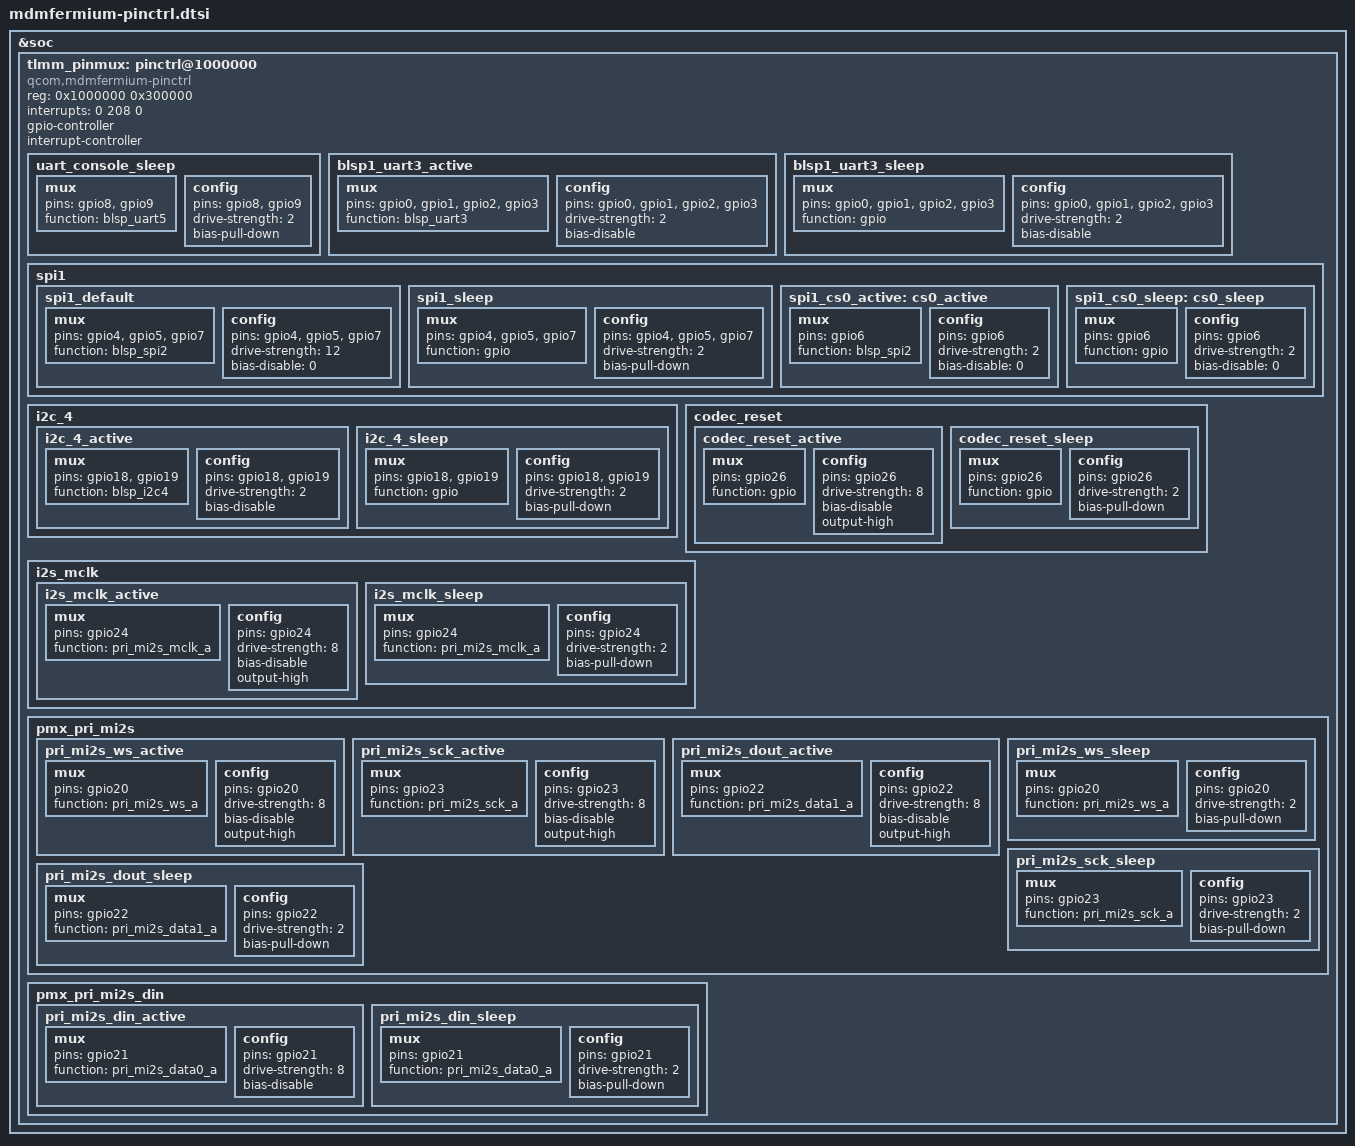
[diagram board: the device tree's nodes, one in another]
/*
 * Copyright (c) 2015, The Linux Foundation. All rights reserved.
 *
 * This program is free software; you can redistribute it and/or modify
 * it under the terms of the GNU General Public License version 2 and
 * only version 2 as published by the Free Software Foundation.
 *
 * This program is distributed in the hope that it will be useful,
 * but WITHOUT ANY WARRANTY; without even the implied warranty of
 * MERCHANTABILITY or FITNESS FOR A PARTICULAR PURPOSE.  See the
 * GNU General Public License for more details.
 */

&soc {
	tlmm_pinmux: pinctrl@1000000 {
		compatible = "qcom,mdmfermium-pinctrl";
		reg = <0x1000000 0x300000>;
		interrupts = <0 208 0>;
		gpio-controller;
		#gpio-cells = <2>;
		interrupt-controller;
		#interrupt-cells = <2>;

		uart_console_sleep: uart_console_sleep {
			mux {
				pins = "gpio8", "gpio9";
				function = "blsp_uart5";
			};
			config {
				pins = "gpio8", "gpio9";
				drive-strength = <2>;
				bias-pull-down;
			};
		};

		blsp1_uart3_active: blsp1_uart3_active {
			mux {
				pins = "gpio0", "gpio1", "gpio2", "gpio3";
				function = "blsp_uart3";
			};

			config {
				pins = "gpio0", "gpio1", "gpio2", "gpio3";
				drive-strength = <2>;
				bias-disable;
			};
		};

		blsp1_uart3_sleep: blsp1_uart3_sleep {
			mux {
				pins = "gpio0", "gpio1", "gpio2", "gpio3";
				function = "gpio";
			};


			config {
				pins = "gpio0", "gpio1", "gpio2", "gpio3";
				drive-strength = <2>;
				bias-disable;
			};
		};

		spi1 {

			spi1_default: spi1_default {
				/* active state */
				mux {
					/* MOSI, MISO, CLK */
					pins = "gpio4", "gpio5", "gpio7";
					function = "blsp_spi2";
				};

				config {
					pins = "gpio4", "gpio5", "gpio7";
					drive-strength = <12>; /* 12 MA */
					bias-disable = <0>; /* No PULL */
				};
			};


			spi1_sleep: spi1_sleep {
				/* suspended state */
				mux {
					/* MOSI, MISO, CLK */
					pins = "gpio4", "gpio5", "gpio7";
					function = "gpio";
				};

				config {
					pins = "gpio4", "gpio5", "gpio7";
					drive-strength = <2>; /* 2 MA */
					bias-pull-down; /* PULL Down */
				};
			};

			spi1_cs0_active: cs0_active {
				/* CS */
				mux {
					pins = "gpio6";
					function = "blsp_spi2";
				};

				config {
					pins = "gpio6";
					drive-strength = <2>;
					bias-disable = <0>;
				};
			};

			spi1_cs0_sleep: cs0_sleep {
				/* CS */
				mux {
					pins = "gpio6";
					function = "gpio";
				};

				config {
					pins = "gpio6";
					drive-strength = <2>;
					bias-disable = <0>;
				};
			};
		};


		i2c_4 {
			i2c_4_active: i2c_4_active {
				/* active state */
				mux {
					pins = "gpio18", "gpio19";
					function = "blsp_i2c4";
				};
				config {
					pins = "gpio18", "gpio19";
					drive-strength = <2>;
					bias-disable;
				};
			};

			i2c_4_sleep: i2c_4_sleep {
				/* suspended state */
				mux {
					pins = "gpio18", "gpio19";
					function = "gpio";
				};
				config {
					pins = "gpio18", "gpio19";
					drive-strength = <2>;
					bias-pull-down;
				};
			};
		};

		codec_reset {
			codec_reset_active: codec_reset_active {
				mux {
					pins = "gpio26";
					function = "gpio";
				};
				config {
					pins = "gpio26";
					drive-strength = <8>;   /* 8 MA */
					bias-disable;           /* No PULL */
					output-high;
				};
			};
			codec_reset_sleep: codec_reset_sleep {
				mux {
					pins = "gpio26";
					function = "gpio";
				};
				config {
					pins = "gpio26";
					drive-strength = <2>;   /* 2 MA */
					bias-pull-down;	        /* PULL DOWN */
				};
			};
		};

		i2s_mclk {
			i2s_mclk_active: i2s_mclk_active {
				mux {
					pins = "gpio24";
					function = "pri_mi2s_mclk_a";
				};
				config {
					pins = "gpio24";
					drive-strength = <8>;   /* 8 MA */
					bias-disable;           /* No PULL */
					output-high;
				};
			};
			i2s_mclk_sleep: i2s_mclk_sleep {
				mux {
					pins = "gpio24";
					function = "pri_mi2s_mclk_a";
				};
				config {
					pins = "gpio24";
					drive-strength = <2>;   /* 2 MA */
					bias-pull-down;	        /* PULL DOWN */
				};
			};
		};

		pmx_pri_mi2s {
				pri_mi2s_ws_active: pri_mi2s_ws_active {
				mux {
					pins = "gpio20";
					function = "pri_mi2s_ws_a";
				};
				config {
					pins = "gpio20";
					drive-strength = <8>;   /* 8 MA */
					bias-disable;           /* No PULL */
					output-high;
				};
			};

			pri_mi2s_sck_active: pri_mi2s_sck_active {
				mux {
					pins = "gpio23";
					function = "pri_mi2s_sck_a";
				};

				config {
					pins = "gpio23";
					drive-strength = <8>;   /* 8 MA */
					bias-disable;           /* No PULL */
					output-high;
				};
			};

			pri_mi2s_dout_active: pri_mi2s_dout_active {
				mux {
					pins = "gpio22";
					function = "pri_mi2s_data1_a";
				};
				config {
					pins = "gpio22";
					drive-strength = <8>;   /* 8 MA */
					bias-disable;           /* No PULL */
					output-high;
				};
			};

			pri_mi2s_ws_sleep: pri_mi2s_ws_sleep {
				mux {
					pins = "gpio20";
					function = "pri_mi2s_ws_a";
				};
				config {
					pins = "gpio20";
					drive-strength = <2>;   /* 2 MA */
					bias-pull-down;	        /* PULL DOWN */
				};
			};

			pri_mi2s_sck_sleep: pri_mi2s_sck_sleep {
				mux {
					pins = "gpio23";
					function = "pri_mi2s_sck_a";
				};
				config {
					pins = "gpio23";
					drive-strength = <2>;   /* 2 MA */
					bias-pull-down;	        /* PULL DOWN */
				};
			};

			pri_mi2s_dout_sleep: pri_mi2s_dout_sleep {
				mux {
					pins = "gpio22";
					function = "pri_mi2s_data1_a";
				};

				config {
					pins = "gpio22";
					drive-strength = <2>;   /* 2 MA */
					bias-pull-down;	        /* PULL DOWN */
				};
			};
		};

		pmx_pri_mi2s_din {
				pri_mi2s_din_active: pri_mi2s_din_active {
				mux {
					pins = "gpio21";
					function = "pri_mi2s_data0_a";
				};
				config {
					pins = "gpio21";
					drive-strength = <8>;   /* 8 MA */
					bias-disable;	        /* No PULL */
				};
			};

			pri_mi2s_din_sleep: pri_mi2s_din_sleep {
				mux {
					pins = "gpio21";
					function = "pri_mi2s_data0_a";
				};
				config {
					pins = "gpio21";
					drive-strength = <2>;   /* 2 MA */
					bias-pull-down;	        /* PULL DOWN */
				};
			};
		};
	};
};
